VERSION ""

NS_ :

BS_:

BU_:

BO_ 515 C_TH01_MSG2: 4 Vector__XXX
 SG_ D22 : 23|16@0- (0.1,0) [-3276.6|3276.7] "DegreeC" Vector__XXX
 SG_ D13 : 7|16@0- (0.1,0) [-3276.6|3276.7] "DegreeC" Vector__XXX

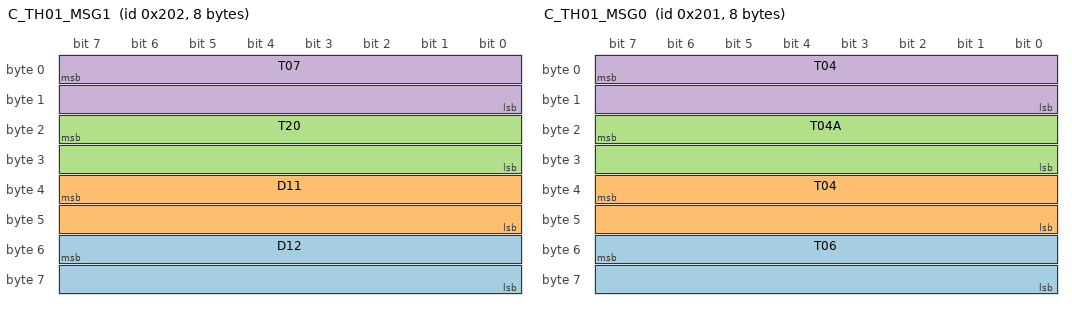
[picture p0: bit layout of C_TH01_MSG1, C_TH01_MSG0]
BO_ 514 C_TH01_MSG1: 8 Vector__XXX
 SG_ D12 : 55|16@0- (0.1,0) [-3276.6|3276.7] "DegreeC" Vector__XXX
 SG_ D11 : 39|16@0- (0.1,0) [-3276.6|3276.7] "DegreeC" Vector__XXX
 SG_ T20 : 23|16@0- (0.1,0) [-3276.6|3276.7] "DegreeC" Vector__XXX
 SG_ T07 : 7|16@0- (0.1,0) [-3276.6|3276.7] "DegreeC" Vector__XXX

BO_ 513 C_TH01_MSG0: 8 Vector__XXX
 SG_ T06 : 55|16@0- (0.1,0) [-3276.6|3276.7] "DegreeC" Vector__XXX
 SG_ T04 : 39|16@0- (0.1,0) [-3276.6|3276.7] "DegreeC" Vector__XXX
 SG_ T04A : 23|16@0- (0.1,0) [-3276.6|3276.7] "DegreeC" Vector__XXX
 SG_ T04 : 7|16@0- (0.1,0) [-3276.8|3276.7] "DegreeC" Vector__XXX

BO_ 1761 C_LAM01_MSG2: 2 Vector__XXX
 SG_ cLAM01_Ip : 0|16@1- (0.0001,0) [-3.2768|3.2767] "mA" Vector__XXX

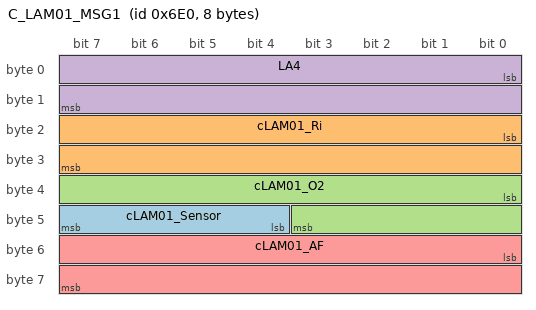
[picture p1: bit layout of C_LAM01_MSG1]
BO_ 1760 C_LAM01_MSG1: 8 Vector__XXX
 SG_ cLAM01_Sensor : 44|4@1+ (1,0) [0|15] "%" Vector__XXX
 SG_ cLAM01_Ri : 16|16@1+ (0.1,0) [0|6553.5] "Ohm" Vector__XXX
 SG_ cLAM01_O2 : 32|12@1+ (0.01,0) [0|40.95] "%" Vector__XXX
 SG_ LA4 : 0|16@1+ (0.001,0) [0|65.535] "" Vector__XXX
 SG_ cLAM01_AF : 48|16@1+ (0.01,0) [0|655.35] "" Vector__XXX
